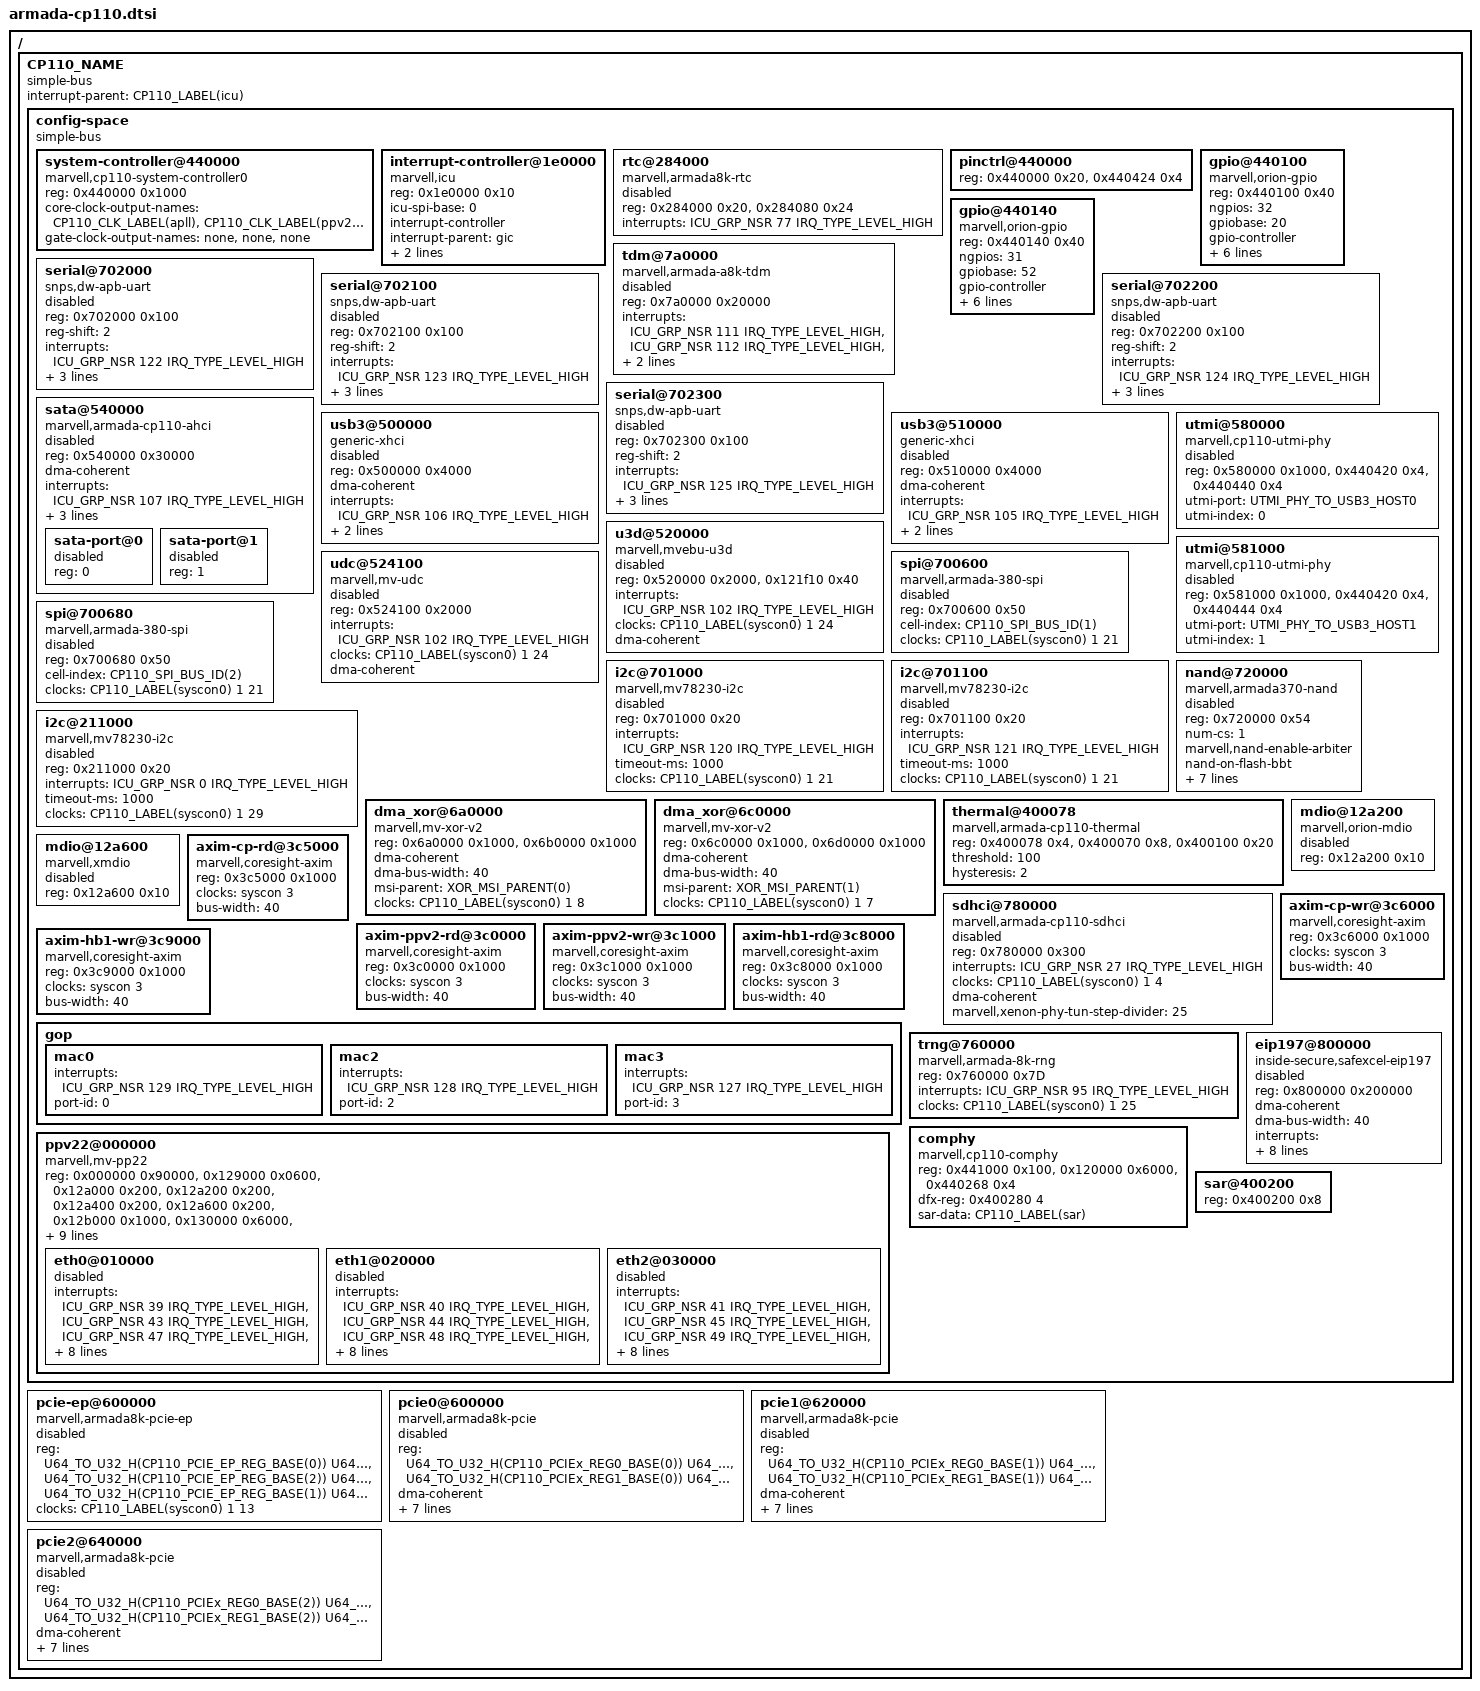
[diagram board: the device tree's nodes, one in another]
/****************************************************************************
* This program is free software: you can redistribute it and/or modify it
* under the terms of the GNU General Public License as published by the Free
* Software Foundation, either version 2 of the License, or any later version.
*
* This program is distributed in the hope that it will be useful,
* but WITHOUT ANY WARRANTY; without even the implied warranty of
* MERCHANTABILITY or FITNESS FOR A PARTICULAR PURPOSE.  See the
* GNU General Public License for more details.
*
* You should have received a copy of the GNU General Public License
* along with this program.  If not, see <http://www.gnu.org/licenses/>.
* ***************************************************************************
*/

/*
 * Generic Device Tree describing Marvell Armada CP-110 device
 */
#include <dt-bindings/interrupt-controller/mvebu-icu.h>
#include <dt-bindings/phy/phy-utmi-mvebu.h>

#define U64_TO_U32_H(addr)			(((addr) >> 32) & 0xffffffff)
#define U64_TO_U32_L(addr)			((addr) & 0xffffffff)

#define CP110_PCIEx_REG0_BASE(iface)		(CP110_BASE + 0x600000 + (iface) * 0x20000)
#define CP110_PCIEx_REG1_BASE(iface)		(CP110_PCIEx_CPU_MEM_BASE(iface) + CP110_PCIE_MEM_SIZE)

#define CP110_PCIE_EP_REG_BASE(num)		(CP110_BASE + 0x600000 + (num) * 0x4000)

#define CP110_EIP197_INDEX			CP110_NUM
#define CP110_SPI_BUS_ID(n)			((CP110_NUM * 2) + (n))

/ {
	CP110_NAME {
		#address-cells = <2>;
		#size-cells = <2>;
		compatible = "simple-bus";
		interrupt-parent = <&CP110_LABEL(icu)>;
		ranges;

		config-space {
			#address-cells = <1>;
			#size-cells = <1>;
			compatible = "simple-bus";
			ranges = <0x0 U64_TO_U32_H(CP110_BASE) U64_TO_U32_L(CP110_BASE) 0x2000000>;

			CP110_LABEL(syscon0): system-controller@440000 {
				compatible = "marvell,cp110-system-controller0", "syscon";
				reg = <0x440000 0x1000>;
				#clock-cells = <2>;
				core-clock-output-names =
					CP110_CLK_LABEL(apll), CP110_CLK_LABEL(ppv2-core), CP110_CLK_LABEL(eip),
					CP110_CLK_LABEL(core), CP110_CLK_LABEL(nand-core), CP110_CLK_LABEL(emmc);
				gate-clock-output-names =
					CP110_CLK_LABEL(audio), CP110_CLK_LABEL(communit), CP110_CLK_LABEL(nand),
					CP110_CLK_LABEL(ppv2), CP110_CLK_LABEL(sdio), CP110_CLK_LABEL(mg-domain),
					CP110_CLK_LABEL(mg-core), CP110_CLK_LABEL(xor1), CP110_CLK_LABEL(xor0),
					CP110_CLK_LABEL(gop-dp), "none", CP110_CLK_LABEL(pcie_x10),
					CP110_CLK_LABEL(pcie_x11), CP110_CLK_LABEL(pcie_x4), CP110_CLK_LABEL(pcie-xor),
					CP110_CLK_LABEL(sata), CP110_CLK_LABEL(sata-usb), CP110_CLK_LABEL(main),
					CP110_CLK_LABEL(sd-mmc), "none", "none",
					CP110_CLK_LABEL(slow-io), CP110_CLK_LABEL(usb3h0), CP110_CLK_LABEL(usb3h1),
					CP110_CLK_LABEL(usb3dev), CP110_CLK_LABEL(eip150), CP110_CLK_LABEL(eip197);
			};

			CP110_LABEL(icu): interrupt-controller@1e0000 {
				compatible = "marvell,icu";
				reg = <0x1e0000 0x10>;
				#interrupt-cells = <3>;
				#size-cells = <1>;
				#address-cells = <0>;
				icu-spi-base = <0>;
				interrupt-controller;
				interrupt-parent = <&gic>;
				gicp-spi = <AP_ICU_SET_SPI_HIGH AP_ICU_SET_SPI_LOW AP_ICU_CLR_SPI_HIGH AP_ICU_CLR_SPI_LOW>;

			};

			CP110_LABEL(rtc): rtc@284000 {
				compatible = "marvell,armada8k-rtc";
				reg = <0x284000 0x20>, <0x284080 0x24>;
				reg-names = "rtc", "rtc-soc";
				#address-cells = <1>;
				#size-cells = <0>;
				interrupts = <ICU_GRP_NSR 77 IRQ_TYPE_LEVEL_HIGH>;
				status = "disabled";
			};

			CP110_LABEL(pinctrl): pinctrl@440000 {
				reg = <0x440000 0x20>, /* pinctrl regs */
				      <0x440424 0x4>; /* eMMC PHY IO Control 0 Register */
				reg-names = "pinctrl", "mmcio";
			};

			CP110_LABEL(gpio0): gpio@440100 {
				compatible = "marvell,orion-gpio";
				reg = <0x440100 0x40>;
				ngpios = <32>;
				gpiobase = <20>;
				gpio-controller;
				#gpio-cells = <2>;
				interrupt-controller;
				#interrupt-cells = <2>;
				interrupts = <ICU_GRP_NSR 86 IRQ_TYPE_LEVEL_HIGH>,
					   <ICU_GRP_NSR 85 IRQ_TYPE_LEVEL_HIGH>,
					   <ICU_GRP_NSR 84 IRQ_TYPE_LEVEL_HIGH>,
					   <ICU_GRP_NSR 83 IRQ_TYPE_LEVEL_HIGH>;
			};

			CP110_LABEL(gpio1): gpio@440140 {
				compatible = "marvell,orion-gpio";
				reg = <0x440140 0x40>;
				ngpios = <31>;
				gpiobase = <52>;
				gpio-controller;
				#gpio-cells = <2>;
				interrupt-controller;
				#interrupt-cells = <2>;
				interrupts = <ICU_GRP_NSR 82 IRQ_TYPE_LEVEL_HIGH>,
					   <ICU_GRP_NSR 81 IRQ_TYPE_LEVEL_HIGH>,
					   <ICU_GRP_NSR 80 IRQ_TYPE_LEVEL_HIGH>,
					   <ICU_GRP_NSR 79 IRQ_TYPE_LEVEL_HIGH>;
			};

			CP110_LABEL(tdm): tdm@7a0000 {
				compatible = "marvell,armada-a8k-tdm";
				reg = <0x7a0000 0x20000>;
				reg-names = "tdm_regs";
				interrupts = <ICU_GRP_NSR 111 IRQ_TYPE_LEVEL_HIGH>,
					     <ICU_GRP_NSR 112 IRQ_TYPE_LEVEL_HIGH>,
					     <ICU_GRP_NSR 113 IRQ_TYPE_LEVEL_HIGH>;
				clocks = <&CP110_LABEL(syscon0) 1 1>;
				clock-names = "gateclk";
				status = "disabled";
			};

			CP110_LABEL(serial0): serial@702000 {
				compatible = "snps,dw-apb-uart";
				reg = <0x702000 0x100>;
				reg-shift = <2>;
				interrupts = <ICU_GRP_NSR 122 IRQ_TYPE_LEVEL_HIGH>;
				reg-io-width = <1>;
				clocks = <&CP110_LABEL(syscon0) 1  21>, <&CP110_LABEL(syscon0) 1  17>;
				clock-names = "baudclk", "apb_pclk";
				status = "disabled";
			};

			CP110_LABEL(serial1): serial@702100 {
				compatible = "snps,dw-apb-uart";
				reg = <0x702100 0x100>;
				reg-shift = <2>;
				interrupts = <ICU_GRP_NSR 123 IRQ_TYPE_LEVEL_HIGH>;
				reg-io-width = <1>;
				clocks = <&CP110_LABEL(syscon0) 1  21>, <&CP110_LABEL(syscon0) 1  17>;
				clock-names = "baudclk", "apb_pclk";
				status = "disabled";
			};

			CP110_LABEL(serial2): serial@702200 {
				compatible = "snps,dw-apb-uart";
				reg = <0x702200 0x100>;
				reg-shift = <2>;
				interrupts = <ICU_GRP_NSR 124 IRQ_TYPE_LEVEL_HIGH>;
				reg-io-width = <1>;
				clocks = <&CP110_LABEL(syscon0) 1  21>, <&CP110_LABEL(syscon0) 1  17>;
				clock-names = "baudclk", "apb_pclk";
				status = "disabled";
			};

			CP110_LABEL(serial3): serial@702300 {
				compatible = "snps,dw-apb-uart";
				reg = <0x702300 0x100>;
				reg-shift = <2>;
				interrupts = <ICU_GRP_NSR 125 IRQ_TYPE_LEVEL_HIGH>;
				reg-io-width = <1>;
				clocks = <&CP110_LABEL(syscon0) 1  21>, <&CP110_LABEL(syscon0) 1  17>;
				clock-names = "baudclk", "apb_pclk";
				status = "disabled";
			};

			CP110_LABEL(sata): sata@540000 {
				compatible = "marvell,armada-cp110-ahci";
				reg = <0x540000 0x30000>;
				dma-coherent;
				interrupts = <ICU_GRP_NSR 107 IRQ_TYPE_LEVEL_HIGH>;
				clocks = <&CP110_LABEL(syscon0) 1 15>;
				comreset_u = <0x17>;
				comwake = <0x6>;
				status = "disabled";
				#address-cells = <1>;
				#size-cells = <0>;

				sata-port@0 {
					reg = <0>;
					status = "disabled";
				};
				sata-port@1 {
					reg = <1>;
					status = "disabled";
				};
			};

			CP110_LABEL(usb3h0): usb3@500000 {
				compatible = "generic-xhci";
				reg = <0x500000 0x4000>;
				dma-coherent;
				interrupts = <ICU_GRP_NSR 106 IRQ_TYPE_LEVEL_HIGH>;
				clocks = <&CP110_LABEL(syscon0) 1 22>;
				needs-reset-on-resume;
				status = "disabled";
			};

			CP110_LABEL(usb3h1): usb3@510000 {
				compatible = "generic-xhci";
				reg = <0x510000 0x4000>;
				dma-coherent;
				interrupts = <ICU_GRP_NSR 105 IRQ_TYPE_LEVEL_HIGH>;
				clocks = <&CP110_LABEL(syscon0) 1 23>;
				needs-reset-on-resume;
				status = "disabled";
			};

			CP110_LABEL(usb3d): u3d@520000 {
				compatible = "marvell,mvebu-u3d";
				/* 0: 0x520000: USB 3.0 Device port 0: DEV_INFO_REG(0:15 - version_id)
				 * 1: 0x121F10: Clock Source High reg: VBUS present indication in PHY SerDes lane#1
				 */
				reg = <0x520000 0x2000>, <0x121f10 0x40>;
				interrupts = <ICU_GRP_NSR 102 IRQ_TYPE_LEVEL_HIGH>;
				clocks = <&CP110_LABEL(syscon0) 1 24>;
				dma-coherent;
				status = "disabled";
			};

			CP110_LABEL(udc): udc@524100 {
				compatible = "marvell,mv-udc";
				reg = <0x524100 0x2000>;
				interrupts = <ICU_GRP_NSR 102 IRQ_TYPE_LEVEL_HIGH>;
				clocks = <&CP110_LABEL(syscon0) 1 24>;
				dma-coherent;
				status = "disabled";
			};

			CP110_LABEL(utmi0): utmi@580000 {
				compatible = "marvell,cp110-utmi-phy";
				reg = <0x580000 0x1000>,
				      <0x440420 0x4>,
				      <0x440440 0x4>;
				reg-names = "utmi", "usb-cfg-reg", "utmi-cfg-reg";
				utmi-port = <UTMI_PHY_TO_USB3_HOST0>;
				utmi-index = <0>;
				#phy-cells = <0>;
				status = "disabled";
			};

			CP110_LABEL(utmi1): utmi@581000 {
				compatible = "marvell,cp110-utmi-phy";
				reg = <0x581000 0x1000>,
				      <0x440420 0x4>,
				      <0x440444 0x4>;
				reg-names = "utmi", "usb-cfg-reg", "utmi-cfg-reg";
				utmi-port = <UTMI_PHY_TO_USB3_HOST1>;
				utmi-index = <1>;
				#phy-cells = <0>;
				status = "disabled";
			};

			CP110_LABEL(spi0): spi@700600 {
				compatible = "marvell,armada-380-spi";
				reg = <0x700600 0x50>;
				#address-cells = <0x1>;
				#size-cells = <0x0>;
				cell-index = <CP110_SPI_BUS_ID(1)>;
				clocks = <&CP110_LABEL(syscon0) 1 21>;
				status = "disabled";
			};

			CP110_LABEL(spi1): spi@700680 {
				compatible = "marvell,armada-380-spi";
				reg = <0x700680 0x50>;
				#address-cells = <0x1>;
				#size-cells = <0x0>;
				cell-index = <CP110_SPI_BUS_ID(2)>;
				clocks = <&CP110_LABEL(syscon0) 1 21>;
				status = "disabled";
			};

			CP110_LABEL(i2c0): i2c@701000 {
				compatible = "marvell,mv78230-i2c";
				reg = <0x701000 0x20>;
				#address-cells = <1>;
				#size-cells = <0>;
				interrupts = <ICU_GRP_NSR 120 IRQ_TYPE_LEVEL_HIGH>;
				timeout-ms = <1000>;
				clocks = <&CP110_LABEL(syscon0) 1 21>;
				status = "disabled";
			};

			CP110_LABEL(i2c1): i2c@701100 {
				compatible = "marvell,mv78230-i2c";
				reg = <0x701100 0x20>;
				#address-cells = <1>;
				#size-cells = <0>;
				interrupts = <ICU_GRP_NSR 121 IRQ_TYPE_LEVEL_HIGH>;
				timeout-ms = <1000>;
				clocks = <&CP110_LABEL(syscon0) 1 21>;
				status = "disabled";
			};

			CP110_LABEL(mss_i2c0): i2c@211000 {
				compatible = "marvell,mv78230-i2c";
				reg = <0x211000 0x20>;
				#address-cells = <1>;
				#size-cells = <0>;
				interrupts = <ICU_GRP_NSR 0 IRQ_TYPE_LEVEL_HIGH>;
				timeout-ms = <1000>;
				clocks = <&CP110_LABEL(syscon0) 1 29>;
				status = "disabled";
			};

			CP110_LABEL(nand): nand@720000 {
				compatible = "marvell,armada370-nand";
				reg = <0x720000 0x54>;
				#address-cells = <1>;
				#size-cells = <1>;
				num-cs = <1>;
				marvell,nand-enable-arbiter;
				nand-on-flash-bbt;
				interrupts = <ICU_GRP_NSR 115 IRQ_TYPE_LEVEL_HIGH>;
				clock-names = "core", "reg", "device_bus";
				clocks = <&CP110_LABEL(syscon0) 1 2>,
					 <&CP110_LABEL(syscon0) 1 17>,
					 <&CP110_LABEL(syscon0) 1 21>;
				nand-ecc-strength = <4>;
				nand-ecc-step-size = <512>;
				status = "disabled";
			};

			CP110_LABEL(xor0): dma_xor@6a0000 {
				compatible = "marvell,mv-xor-v2";
				reg = <0x6a0000 0x1000>,
					<0x6b0000 0x1000>;
				dma-coherent;
				dma-bus-width = <40>;
				msi-parent = XOR_MSI_PARENT(0);
				clocks = <&CP110_LABEL(syscon0) 1 8>;
				status = "okay";
			};

			CP110_LABEL(xor1): dma_xor@6c0000 {
				compatible = "marvell,mv-xor-v2";
				reg = <0x6c0000 0x1000>,
					<0x6d0000 0x1000>;
				dma-coherent;
				dma-bus-width = <40>;
				msi-parent = XOR_MSI_PARENT(1);
				clocks = <&CP110_LABEL(syscon0) 1 7>;
				status = "okay";
			};

			CP110_LABEL(thermal): thermal@400078 {
				compatible = "marvell,armada-cp110-thermal";
				reg = <0x400078 0x4>,
					<0x400070 0x8>,
					<0x400100 0x20>;
				threshold = <100>;
				hysteresis = <2>;
				status = "okay";
			};

			CP110_LABEL(mdio0): mdio@12a200 {
				#address-cells = <1>;
				#size-cells = <0>;
				compatible = "marvell,orion-mdio";
				reg = <0x12a200 0x10>;
				status = "disabled";
			};

			CP110_LABEL(mdio1): mdio@12a600 {
				#address-cells = <1>;
				#size-cells = <0>;
				compatible = "marvell,xmdio";
				reg = <0x12a600 0x10>;
				status = "disabled";
			};

			CP110_LABEL(sdhci): sdhci@780000 {
				compatible = "marvell,armada-cp110-sdhci";
				reg = <0x780000 0x300>;
				interrupts = <ICU_GRP_NSR 27 IRQ_TYPE_LEVEL_HIGH>;
				clock-names = "core";
				clocks = <&CP110_LABEL(syscon0) 1 4>;
				dma-coherent;
				marvell,xenon-phy-tun-step-divider = <25>;
				status = "disabled";
			};

			CP110_LABEL(axim_cp_rd): axim-cp-rd@3c5000 {
				compatible = "marvell,coresight-axim", "arm,primecell";
				reg = <0x3c5000 0x1000>;
				clocks = <&syscon 3>;
				clock-names = "apb_pclk";
				bus-width = <40>;
			};

			CP110_LABEL(axim_cp_wr): axim-cp-wr@3c6000 {
				compatible = "marvell,coresight-axim", "arm,primecell";
				reg = <0x3c6000 0x1000>;
				clocks = <&syscon 3>;
				clock-names = "apb_pclk";
				bus-width = <40>;
			};

			CP110_LABEL(axim_ppv2_rd): axim-ppv2-rd@3c0000 {
				compatible = "marvell,coresight-axim", "arm,primecell";
				reg = <0x3c0000 0x1000>;
				clocks = <&syscon 3>;
				clock-names = "apb_pclk";
				bus-width = <40>;
			};

			CP110_LABEL(axim_ppv2_wr): axim-ppv2-wr@3c1000 {
				compatible = "marvell,coresight-axim", "arm,primecell";
				reg = <0x3c1000 0x1000>;
				clocks = <&syscon 3>;
				clock-names = "apb_pclk";
				bus-width = <40>;
			};

			CP110_LABEL(axim_hb1_rd): axim-hb1-rd@3c8000 {
				compatible = "marvell,coresight-axim", "arm,primecell";
				reg = <0x3c8000 0x1000>;
				clocks = <&syscon 3>;
				clock-names = "apb_pclk";
				bus-width = <40>;
			};

			CP110_LABEL(axim_hb1_wr): axim-hb1-wr@3c9000 {
				compatible = "marvell,coresight-axim", "arm,primecell";
				reg = <0x3c9000 0x1000>;
				clocks = <&syscon 3>;
				clock-names = "apb_pclk";
				bus-width = <40>;
			};

			gop {
				CP110_LABEL(emac0): mac0 {
					interrupts = <ICU_GRP_NSR 129 IRQ_TYPE_LEVEL_HIGH>;  /* Link IRQ */
					port-id = <0>; /* gop_port_id */
				};
				CP110_LABEL(emac2): mac2 {
					interrupts = <ICU_GRP_NSR 128 IRQ_TYPE_LEVEL_HIGH>;  /* Link IRQ */
					port-id = <2>; /* gop_port_id */
				};
				CP110_LABEL(emac3): mac3 {
					interrupts = <ICU_GRP_NSR 127 IRQ_TYPE_LEVEL_HIGH>;  /* Link IRQ */
					port-id = <3>; /* gop_port_id */
				};
			};

			CP110_LABEL(ppv22): ppv22@000000 {
				compatible = "marvell,mv-pp22";
				reg = <0x000000 0x90000>, /* Packet Processor regs */
					<0x129000 0x0600>, /* XMIB regs */
					<0x12a000 0x200>,  /* LED regs */
					<0x12a200 0x200>,  /* SMI regs */
					<0x12a400 0x200>,  /* TAI regs */
					<0x12a600 0x200>,  /* XSMI regs */
					<0x12b000 0x1000>,  /* MG Internal regs */
					<0x130000 0x6000>, /* MSPG regs */
					<0x130400 0x200>,  /* MSPG - XPCS regs */
					<0x130600 0x200>,  /* FCA - flow control regs*/
					<0x130e00 0x100>,  /* MSPG - GMAC regs */
					<0x130f00 0x100>,  /* MSPG - XLG MAC regs */
					<0x441100 0x100>,  /* RFU-1 Regs */
					<0x220000 0x800>;  /* CM3 SRAM */
				reg-names = "pp", "xmib", "led", "smi", "tai", "xsmi", "mg", "mspg", "xpcs",
						"fca", "gmac", "xlg", "rfu1", "cm3";
				clocks = <&CP110_LABEL(syscon0) 1 3>, <&CP110_LABEL(syscon0) 1 18>, <&CP110_LABEL(syscon0) 1 9>,
					<&CP110_LABEL(syscon0) 1 6>, <&CP110_LABEL(syscon0) 1 5>;
				clock-names = "pp_clk", "gop_core_clk", "gop_clk", "mg_core_clk", "mg_clk";
				status = "okay";
				dma-coherent;
				CP110_LABEL(eth0): eth0@010000 {
					interrupts = <ICU_GRP_NSR 39 IRQ_TYPE_LEVEL_HIGH>,
							<ICU_GRP_NSR 43 IRQ_TYPE_LEVEL_HIGH>,
							<ICU_GRP_NSR 47 IRQ_TYPE_LEVEL_HIGH>,
							<ICU_GRP_NSR 51 IRQ_TYPE_LEVEL_HIGH>,
							<ICU_GRP_NSR 55 IRQ_TYPE_LEVEL_HIGH>,
							<ICU_GRP_NSR 59 IRQ_TYPE_LEVEL_HIGH>,
							<ICU_GRP_NSR 63 IRQ_TYPE_LEVEL_HIGH>,
							<ICU_GRP_NSR 67 IRQ_TYPE_LEVEL_HIGH>,
							<ICU_GRP_NSR 71 IRQ_TYPE_LEVEL_HIGH>;
					port-id = <0>; /* pp2_port_id */
					emac-data = <&CP110_LABEL(emac0)>;
					status = "disabled";
				};
				CP110_LABEL(eth1): eth1@020000 {
					interrupts = <ICU_GRP_NSR 40 IRQ_TYPE_LEVEL_HIGH>,
							<ICU_GRP_NSR 44 IRQ_TYPE_LEVEL_HIGH>,
							<ICU_GRP_NSR 48 IRQ_TYPE_LEVEL_HIGH>,
							<ICU_GRP_NSR 52 IRQ_TYPE_LEVEL_HIGH>,
							<ICU_GRP_NSR 56 IRQ_TYPE_LEVEL_HIGH>,
							<ICU_GRP_NSR 60 IRQ_TYPE_LEVEL_HIGH>,
							<ICU_GRP_NSR 64 IRQ_TYPE_LEVEL_HIGH>,
							<ICU_GRP_NSR 68 IRQ_TYPE_LEVEL_HIGH>,
							<ICU_GRP_NSR 72 IRQ_TYPE_LEVEL_HIGH>;
					port-id = <1>; /* pp2_port_id */
					emac-data = <&CP110_LABEL(emac2)>;
					status = "disabled";
				};
				CP110_LABEL(eth2): eth2@030000 {
					interrupts = <ICU_GRP_NSR 41 IRQ_TYPE_LEVEL_HIGH>,
							<ICU_GRP_NSR 45 IRQ_TYPE_LEVEL_HIGH>,
							<ICU_GRP_NSR 49 IRQ_TYPE_LEVEL_HIGH>,
							<ICU_GRP_NSR 53 IRQ_TYPE_LEVEL_HIGH>,
							<ICU_GRP_NSR 57 IRQ_TYPE_LEVEL_HIGH>,
							<ICU_GRP_NSR 61 IRQ_TYPE_LEVEL_HIGH>,
							<ICU_GRP_NSR 65 IRQ_TYPE_LEVEL_HIGH>,
							<ICU_GRP_NSR 69 IRQ_TYPE_LEVEL_HIGH>,
							<ICU_GRP_NSR 73 IRQ_TYPE_LEVEL_HIGH>;
					port-id = <2>; /* pp2_port_id */
					emac-data = <&CP110_LABEL(emac3)>;
					status = "disabled";
				};
			};

			CP110_LABEL(trng): trng@760000 {
				compatible = "marvell,armada-8k-rng", "inside-secure,safexcel-eip76";
				reg = <0x760000 0x7D>;
				#address-cells = <1>;
				#size-cells = <0>;
				interrupts = <ICU_GRP_NSR 95 IRQ_TYPE_LEVEL_HIGH>;
				clocks = <&CP110_LABEL(syscon0) 1 25>;
				status = "okay";
			};

			CP110_LABEL(eip197): eip197@800000 {
				compatible = "inside-secure,safexcel-eip197";
				reg = <0x800000 0x200000>;
				dma-coherent;
				dma-bus-width = <40>;
				interrupts = <ICU_GRP_REI 87 IRQ_TYPE_LEVEL_HIGH>,
						<ICU_GRP_NSR 88 IRQ_TYPE_LEVEL_HIGH>,
						<ICU_GRP_NSR 89 IRQ_TYPE_LEVEL_HIGH>,
						<ICU_GRP_NSR 90 IRQ_TYPE_LEVEL_HIGH>,
						<ICU_GRP_NSR 91 IRQ_TYPE_LEVEL_HIGH>,
						<ICU_GRP_NSR 92 IRQ_TYPE_LEVEL_HIGH>;
				interrupt-names = "eip_addr", "ring0", "ring1",
						"ring2", "ring3", "eip_out";
				clocks = <&CP110_LABEL(syscon0) 1 26>;
				cell-index = <CP110_EIP197_INDEX>;
				status = "disabled";
			};

			CP110_LABEL(comphy): comphy {
				compatible = "marvell,cp110-comphy";
				reg = <0x441000 0x100>, <0x120000 0x6000>, <0x440268 0x4>;
				reg-names = "comphy", "serdes", "mac_reset";
				dfx-reg = <0x400280 4>;
				#phy-cells = <2>;
				sar-data = <&CP110_LABEL(sar)>;
			};

			CP110_LABEL(sar): sar@400200 {
				reg = <0x400200 0x8>;
				status = "okay";
			};
		};

		CP110_LABEL(pcie_ep): pcie-ep@600000 {
			compatible = "marvell,armada8k-pcie-ep", "snps,dw-pcie";
			reg =
			   <U64_TO_U32_H(CP110_PCIE_EP_REG_BASE(0)) U64_TO_U32_L(CP110_PCIE_EP_REG_BASE(0)) 0 0x4000>,
			   <U64_TO_U32_H(CP110_PCIE_EP_REG_BASE(2)) U64_TO_U32_L(CP110_PCIE_EP_REG_BASE(2)) 0 0x80000>,
			   <U64_TO_U32_H(CP110_PCIE_EP_REG_BASE(1)) U64_TO_U32_L(CP110_PCIE_EP_REG_BASE(1)) 0 0x1000>;
			reg-names = "core", "lm", "shadow_core";
			clocks = <&CP110_LABEL(syscon0) 1 13>;
			status = "disabled";
		};

		CP110_LABEL(pcie0): pcie0@600000 {
			compatible = "marvell,armada8k-pcie", "snps,dw-pcie";
			reg =
			   <U64_TO_U32_H(CP110_PCIEx_REG0_BASE(0)) U64_TO_U32_L(CP110_PCIEx_REG0_BASE(0)) 0 0x10000>,
			   /* Last 512KB of mem space */
			   <U64_TO_U32_H(CP110_PCIEx_REG1_BASE(0)) U64_TO_U32_L(CP110_PCIEx_REG1_BASE(0)) 0 0x80000>;
			reg-names = "ctrl", "config";
			#address-cells = <3>;
			#size-cells = <2>;
			#interrupt-cells = <1>;
			device_type = "pci";
			dma-coherent;

			bus-range = <0 0xff>;
			ranges =
				/* downstream I/O */
				<0x81000000 U64_TO_U32_H(CP110_PCIEx_BUS_IO_BASE(0))
				U64_TO_U32_L(CP110_PCIEx_BUS_IO_BASE(0)) U64_TO_U32_H(CP110_PCIEx_CPU_IO_BASE(0))
				U64_TO_U32_L(CP110_PCIEx_CPU_IO_BASE(0)) 0 0x10000
				/* non-prefetchable memory */
				CP110_PCIE_BUS_MEM_CFG U64_TO_U32_H(CP110_PCIEx_BUS_MEM_BASE(0))
				U64_TO_U32_L(CP110_PCIEx_BUS_MEM_BASE(0)) U64_TO_U32_H(CP110_PCIEx_CPU_MEM_BASE(0))
				U64_TO_U32_L(CP110_PCIEx_CPU_MEM_BASE(0)) U64_TO_U32_H(CP110_PCIE_MEM_SIZE)
				U64_TO_U32_L(CP110_PCIE_MEM_SIZE)>;
			interrupt-map-mask = <0 0 0 0>;
			interrupt-map = <0 0 0 0 &CP110_LABEL(icu) ICU_GRP_NSR 22 IRQ_TYPE_LEVEL_HIGH>;
			interrupts = <ICU_GRP_NSR 22 IRQ_TYPE_LEVEL_HIGH>;
			num-lanes = <1>;
			clocks = <&CP110_LABEL(syscon0) 1 13>;
			status = "disabled";
		};

		CP110_LABEL(pcie1): pcie1@620000 {
			compatible = "marvell,armada8k-pcie", "snps,dw-pcie";
			reg =
			   <U64_TO_U32_H(CP110_PCIEx_REG0_BASE(1)) U64_TO_U32_L(CP110_PCIEx_REG0_BASE(1)) 0 0x10000>,
			   /* Last 512KB of mem space */
			   <U64_TO_U32_H(CP110_PCIEx_REG1_BASE(1)) U64_TO_U32_L(CP110_PCIEx_REG1_BASE(1)) 0 0x80000>;
			reg-names = "ctrl", "config";
			#address-cells = <3>;
			#size-cells = <2>;
			#interrupt-cells = <1>;
			device_type = "pci";
			dma-coherent;

			bus-range = <0 0xff>;
			ranges =
				/* downstream I/O */
				<0x81000000 U64_TO_U32_H(CP110_PCIEx_BUS_IO_BASE(1))
				U64_TO_U32_L(CP110_PCIEx_BUS_IO_BASE(1)) U64_TO_U32_H(CP110_PCIEx_CPU_IO_BASE(1))
				U64_TO_U32_L(CP110_PCIEx_CPU_IO_BASE(1)) 0 0x10000
				/* non-prefetchable memory */
				CP110_PCIE_BUS_MEM_CFG U64_TO_U32_H(CP110_PCIEx_BUS_MEM_BASE(1))
				U64_TO_U32_L(CP110_PCIEx_BUS_MEM_BASE(1)) U64_TO_U32_H(CP110_PCIEx_CPU_MEM_BASE(1))
				U64_TO_U32_L(CP110_PCIEx_CPU_MEM_BASE(1)) U64_TO_U32_H(CP110_PCIE_MEM_SIZE)
				U64_TO_U32_L(CP110_PCIE_MEM_SIZE)>;
			interrupt-map-mask = <0 0 0 0>;
			interrupt-map = <0 0 0 0 &CP110_LABEL(icu) ICU_GRP_NSR 24 IRQ_TYPE_LEVEL_HIGH>;
			interrupts = <ICU_GRP_NSR 24 IRQ_TYPE_LEVEL_HIGH>;

			num-lanes = <1>;
			clocks = <&CP110_LABEL(syscon0) 1 11>;
			status = "disabled";
		};

		CP110_LABEL(pcie2): pcie2@640000 {
			compatible = "marvell,armada8k-pcie", "snps,dw-pcie";
			reg =
			   <U64_TO_U32_H(CP110_PCIEx_REG0_BASE(2)) U64_TO_U32_L(CP110_PCIEx_REG0_BASE(2)) 0 0x10000>,
			   /* Last 64KB of mem space */
			   <U64_TO_U32_H(CP110_PCIEx_REG1_BASE(2)) U64_TO_U32_L(CP110_PCIEx_REG1_BASE(2)) 0 0x80000>;
			reg-names = "ctrl", "config";
			#address-cells = <3>;
			#size-cells = <2>;
			#interrupt-cells = <1>;
			device_type = "pci";
			dma-coherent;

			bus-range = <0 0xff>;
			ranges =
				/* downstream I/O */
				<0x81000000 U64_TO_U32_H(CP110_PCIEx_BUS_IO_BASE(2))
				U64_TO_U32_L(CP110_PCIEx_BUS_IO_BASE(2)) U64_TO_U32_H(CP110_PCIEx_CPU_IO_BASE(2))
				U64_TO_U32_L(CP110_PCIEx_CPU_IO_BASE(2)) 0 0x10000
				/* non-prefetchable memory */
				CP110_PCIE_BUS_MEM_CFG U64_TO_U32_H(CP110_PCIEx_BUS_MEM_BASE(2))
				U64_TO_U32_L(CP110_PCIEx_BUS_MEM_BASE(2)) U64_TO_U32_H(CP110_PCIEx_CPU_MEM_BASE(2))
				U64_TO_U32_L(CP110_PCIEx_CPU_MEM_BASE(2)) U64_TO_U32_H(CP110_PCIE_MEM_SIZE)
				U64_TO_U32_L(CP110_PCIE_MEM_SIZE)>;
			interrupt-map-mask = <0 0 0 0>;
			interrupt-map = <0 0 0 0 &CP110_LABEL(icu) ICU_GRP_NSR 23 IRQ_TYPE_LEVEL_HIGH>;
			interrupts = <ICU_GRP_NSR 23 IRQ_TYPE_LEVEL_HIGH>;

			num-lanes = <1>;
			clocks = <&CP110_LABEL(syscon0) 1 12>;
			status = "disabled";
		};
	};
};
